# YTM32B1LE0 register map
Vendor: YTMicro; File version: 1.9
CPU: CM0PLUS r0p1, little endian, MPU, FPU, 2 interrupt priority bits
Registers are 32-bit, read-write, reset 0x0 unless marked. A register's access mark holds for its fields unless they carry their own. Offsets are from the block's base; [hi:lo] are bit positions; 'fields as' and 'values as' point back to an identical list; <NAME> marks a mode.

## EFM — Embedded FLASH Module
Base 0x40020000; register names take the prefix EFM_
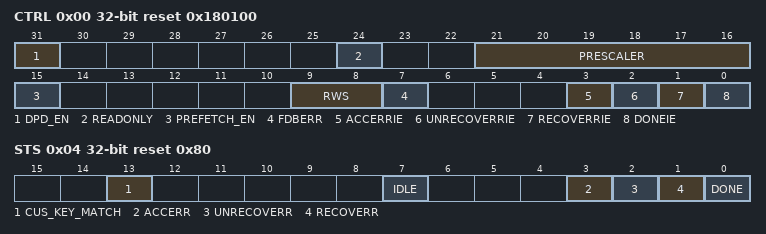
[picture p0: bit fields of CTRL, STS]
0x00 CTRL reset 0x180100
  [31] DPD_EN — This DPD_EN bit determines whether the flash will enter deep power-down mode when MCU is entering Deepsleep mode.
    0=Flash will stay active when MCU enters Deepsleep mode; 1=Flash will enter deep power-down mode when MCU enters Deepsleep mode
  [24] READONLY — Program and erase operation will be aborted immediately, and only read access can be executed. Note that this bit is write-only, always get back 0 when read this bit.
    0=Read, program and erase function are enabled; 1=Only read operation to Flash is enabled
  [21:16] PRESCALER — These PRESCALER bits are used for flash operation timing control. ewline Please make sure PRESCALER to be the value of slow bus frequency.
  [15] PREFETCH_EN — This PREFETCH_EN bit is used for enabling prefetch read functionality.
  [9:8] RWS — These RWS bits determine clock cycles number that needs to be waited to get the flash data out after flash received the read access signal. ewline Please use the following equation to calculate the RWS value: ewline (core frequency/(RWS+1)) <= 24MHz ewline If core frequency is less than 24MHz, the RWS should be set to 0. ewline Please note that once the core frequency is changed, this field needs to be set to the appropriate value.
  [7] FDBERR — This FDBERR bit will generate unrecovery ecc error for each read access.
    0=Disable generating unrecovery ecc error; 1=Enable generating unrecovery ecc error
  [3] ACCERRIE — This ACCERRIE bit determines whether the interrupt will be generated if ACCERR flag is asserted.
    0=Disable generating interrupt if ACCERR flag is asserted; 1=Enable generating interrupt if ACCERR flag is asserted
  [2] UNRECOVERRIE — This UNRECOVERRIE bit determines whether the interrupt will be generated if UNRECOVERR flag is asserted.
    0=Disable generating interrupt if UNRECOVERR flag is asserted; 1=Enable generating interrupt if UNRECOVERR flag is asserted
  [1] RECOVERRIE — This RECOVERRIE bit determines whether the interrupt will be generated if RECOVERR flag is asserted.
    0=Disable generating interrupt if RECOVERR flag is asserted; 1=Enable generating interrupt if RECOVERR flag is asserted
  [0] DONEIE — This DONEIE bit determines whether the interrupt will be generated if DONE flag is asserted.
    0=Disable generating interrupt if DONE flag is asserted; 1=Enable generating interrupt if DONE flag is asserted
0x04 STS reset 0x80
  [13] CUS_KEY_MATCH ro — This bit indicates whether the customer key is matched.
    0=Customer key is not matched; 1=Customer key is matched
  [7] IDLE ro — This IDLE bit indicates whether flash is executing a command.
    0=Flash is currently executing a command; 1=No command is currently being executed
  [3] ACCERR — This ACCERR bit indicates whether an access error been detected. ewline Accerr error includes below scenarios: ewline 1.Access flash when IDLE is de-asserted. ewline 2.Launch a new command when IDLE is de-asserted. ewline 3.Lack of address or data information before launching the program or erase command.
    0=Access error is not detected; 1=Access error is detected
  [2] UNRECOVERR — This UNRECOVERR bit indicates whether an unrecoverable ecc error been detected.
    0=Unrecoverry ecc error is not detected; 1=Unrecoverry ecc error is detected
  [1] RECOVERR — This RECOVERR bit indicates whether a recoverable ecc error been detected.
    0=Recovery ecc error is not detected; 1=Recovery ecc error is detected
  [0] DONE — This DONE bit indicates whether the current command is completed.
    0=Current command is in progress; 1=Current command is completed
0x08 CMD
  [7:0] CMD — These CMD bits determine which commands are available.
    2=Program 32 bits; 16=Erase sector; 18=Erase Block (only main array)
0x24 AP0 reset 0xFFFFFFFF
  [31:0] ADDR_PROT — Each bit protects 2K bytes address area. ewline if the bit is set to 0, the corresponding 2K area is under protection.
0x28 AP1 reset 0xFFFFFFFF
  fields as AP0
0x200 CMD_UNLOCK wo
  [31:0] KEY rw — Please write 0xfd9573f5 before launching any command
0x204 CUS_KEY wo
  [31:0] KEY rw — Please write Customer key (0x4dff32) before accessing to Customer NVR. ewline If the key is not matched, accessing to Customer NVR will generate HARDFAULT.
0x300 CTRL_OVRD
  [1] DBG_DISABLE — This bit determines whether the debugger is override disabled.
    0=Debugger is not override disabled; 1=Debugger is override disabled

## Notices in the file
YTMicro Microcontroller all rights reserved.
